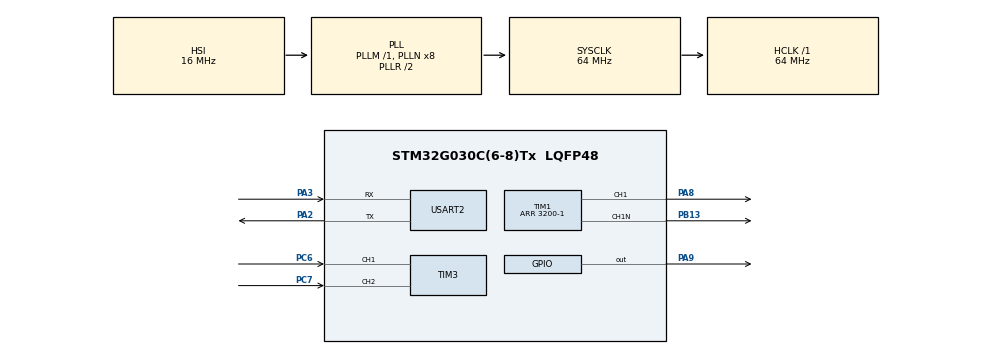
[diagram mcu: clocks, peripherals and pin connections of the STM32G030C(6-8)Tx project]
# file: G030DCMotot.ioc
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Mcu.Family=STM32G0
Mcu.Name=STM32G030C(6-8)Tx
Mcu.Package=LQFP48
NVIC.TIM16_IRQn=true\:0\:0\:false\:false\:true\:true\:true
NVIC.TIM3_IRQn=true\:0\:0\:false\:false\:true\:true\:true
NVIC.USART2_IRQn=true\:0\:0\:false\:false\:true\:true\:true
PA2.Mode=Asynchronous
PA2.Signal=USART2_TX
PA3.Mode=Asynchronous
PA3.Signal=USART2_RX
PA8.Signal=S_TIM1_CH1
PA9.Signal=GPIO_Output
PB13.Mode=PWM Generation1 CH1 CH1N
PB13.Signal=TIM1_CH1N
PC6.Signal=S_TIM3_CH1
PC7.Signal=S_TIM3_CH2
ProjectManager.HeapSize=0x200
ProjectManager.StackSize=0x400
ProjectManager.TargetToolchain=MDK-ARM V5.32
RCC.ADCFreq_Value=64000000
RCC.AHBFreq_Value=64000000
RCC.CortexFreq_Value=64000000
RCC.EXTERNAL_CLOCK_VALUE=12288000
RCC.HCLKFreq_Value=64000000
RCC.HSE_VALUE=8000000
RCC.HSI_VALUE=16000000
RCC.LSE_VALUE=32768
RCC.SYSCLKFreq_VALUE=64000000
RCC.SYSCLKSource=RCC_SYSCLKSOURCE_PLLCLK
RCC.VCOOutputFreq_Value=128000000
SH.S_TIM1_CH1.0=TIM1_CH1,PWM Generation1 CH1 CH1N
SH.S_TIM3_CH1.0=TIM3_CH1,Encoder_Interface
SH.S_TIM3_CH2.0=TIM3_CH2,Encoder_Interface
TIM1.AutoReloadPreload=TIM_AUTORELOAD_PRELOAD_ENABLE
TIM1.BreakPolarity=TIM_BREAKPOLARITY_LOW
TIM1.Channel-PWM\ Generation1\ CH1\ CH1N=TIM_CHANNEL_1
TIM1.DeadTime=0xF
TIM1.OCFastMode_PWM-PWM\ Generation1\ CH1\ CH1N=TIM_OCFAST_ENABLE
TIM1.OCNPolarity_1=TIM_OCNPOLARITY_LOW
TIM1.OCPolarity_1=TIM_OCPOLARITY_LOW
TIM1.OffStateIDLEMode=TIM_OSSI_DISABLE
TIM1.OffStateRunMode=TIM_OSSR_ENABLE
TIM1.Period=3200-1
TIM1.Pulse-PWM\ Generation1\ CH1\ CH1N=1200
TIM16.Period=1000-1
TIM16.Prescaler=64-1
TIM3.EncoderMode=TIM_ENCODERMODE_TI12
TIM3.IC1Filter=10
TIM3.IC2Filter=10
USART2.VirtualMode-Asynchronous=VM_ASYNC
VP_TIM16_VS_ClockSourceINT.Mode=Enable_Timer
VP_TIM1_VS_ClockSourceINT.Mode=Internal
board=custom

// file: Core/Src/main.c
/* USER CODE BEGIN Header */
/**
 ******************************************************************************
 * @file           : main.c
 * @brief          : Main program body
 ******************************************************************************
 * @attention
 *
 * <h2><center>&copy; Copyright (c) 2022 STMicroelectronics.
 * All rights reserved.</center></h2>
 *
 * This software component is licensed by ST under BSD 3-Clause license,
 * the "License"; You may not use this file except in compliance with the
 * License. You may obtain a copy of the License at:
 *                        opensource.org/licenses/BSD-3-Clause
 *
 ******************************************************************************
 */
/* USER CODE END Header */
#include "main.h"
#include "tim.h"
#include "usart.h"
#include "gpio.h"

/* USER CODE BEGIN Includes */
#include "DCMotor.h"
#include "stdio.h"

/* USER CODE END Includes */

void SystemClock_Config(void);

int main(void)
{

  /* MCU Configuration--------------------------------------------------------*/

  /* Reset of all peripherals, Initializes the Flash interface and the Systick. */
  HAL_Init();

  /* Configure the system clock */
  SystemClock_Config();

  /* Initialize all configured peripherals */
  MX_GPIO_Init();
  MX_TIM3_Init();
  MX_USART2_UART_Init();
  MX_TIM16_Init();
  MX_TIM1_Init();
  /* USER CODE BEGIN 2 */
  printf("\r\n********************DCMotor Program start**************************\r\n");
  dc_motor_encoder_init();
  dcmotor_init();
  motor_pwm_set(3000);
  dcmotor_start();

  /* USER CODE END 2 */

  /* Infinite loop */
  /* USER CODE BEGIN WHILE */
  while (1)
  {
    printf("%d,%f\r\n", (int)gtim_get_encode(), g_motor_data.speed);
    HAL_Delay(10);
    /* USER CODE END WHILE */

  }
}

void SystemClock_Config(void)
{
  RCC_OscInitTypeDef RCC_OscInitStruct = {0};
  RCC_ClkInitTypeDef RCC_ClkInitStruct = {0};

  /** Configure the main internal regulator output voltage
  */
  HAL_PWREx_ControlVoltageScaling(PWR_REGULATOR_VOLTAGE_SCALE1);
  /** Initializes the RCC Oscillators according to the specified parameters
  * in the RCC_OscInitTypeDef structure.
  */
  RCC_OscInitStruct.OscillatorType = RCC_OSCILLATORTYPE_HSI;
  RCC_OscInitStruct.HSIState = RCC_HSI_ON;
  RCC_OscInitStruct.HSIDiv = RCC_HSI_DIV1;
  RCC_OscInitStruct.HSICalibrationValue = RCC_HSICALIBRATION_DEFAULT;
  RCC_OscInitStruct.PLL.PLLState = RCC_PLL_ON;
  RCC_OscInitStruct.PLL.PLLSource = RCC_PLLSOURCE_HSI;
  RCC_OscInitStruct.PLL.PLLM = RCC_PLLM_DIV1;
  RCC_OscInitStruct.PLL.PLLN = 8;
  RCC_OscInitStruct.PLL.PLLP = RCC_PLLP_DIV2;
  RCC_OscInitStruct.PLL.PLLR = RCC_PLLR_DIV2;
  if (HAL_RCC_OscConfig(&RCC_OscInitStruct) != HAL_OK)
  {
    Error_Handler();
  }
  /** Initializes the CPU, AHB and APB buses clocks
  */
  RCC_ClkInitStruct.ClockType = RCC_CLOCKTYPE_HCLK|RCC_CLOCKTYPE_SYSCLK
                              |RCC_CLOCKTYPE_PCLK1;
  RCC_ClkInitStruct.SYSCLKSource = RCC_SYSCLKSOURCE_PLLCLK;
  RCC_ClkInitStruct.AHBCLKDivider = RCC_SYSCLK_DIV1;
  RCC_ClkInitStruct.APB1CLKDivider = RCC_HCLK_DIV1;

  if (HAL_RCC_ClockConfig(&RCC_ClkInitStruct, FLASH_LATENCY_2) != HAL_OK)
  {
    Error_Handler();
  }
}

void Error_Handler(void)
{
  __disable_irq();
  while (1)
  {
  }
}

/************************ (C) COPYRIGHT STMicroelectronics *****END OF FILE****/
